# iND83216 register map
Vendor: Indiemicro; Series: RealplumTiny; File version: 1.00
High performance IC
CPU: CM0 r0p1, selectable endian, no MPU, no FPU, 4 interrupt priority bits
Registers are 32-bit, read-write, no defined reset value unless marked. A register's access mark holds for its fields unless they carry their own. Offsets are from the block's base; lines under a group give offsets from that group; [hi:lo] are bit positions; {n}, {i} and the like mark numbered series; 'fields as' and 'values as' point back to an identical list; <NAME> marks a mode.

## Memory map
0x50000000 CRGA size 0x400 — Clock & Reset Generator
0x50000400 PMUA size 0x400 — Power Management Unit
0x50000800 SYSCTRLA size 0x100 — System configuration and retention memory
0x50000900 TRIMHV size 0x100 — Trim bits & Control bits in 5V power domain
0x50000C00 IOCTRLA size 0x400 — I/O configuration and DFT pin control
0x50001000 WICA size 0x400 — WakeUp Interrupt Controller in CPU Deepsleep Mode
0x50001400 WDTA size 0x400 — Watchdog Timer Registers
0x50004400 GPIO size 0x400 — GPIO bit control and configuration
0x50010000 PWM size 0x800 — Control (and status) registers for the pulse width modulation waveform generator.
0x50010800 PWM_AUX size 0x400 — Control (and status) registers for the pulse width modulation waveform generator.
0x50010C00 LINM size 0x400 — LIN master interface registers
0x50011C00 LINS size 0x400 — LIN slave interface registers
0x50013000 EVTHOLD size 0x400 — Event Hold Control
0x50013400 SAR_CTRL size 0x400 — SAR ADC Interface registers
0x50015400 UART0 size 0x400 — UART Interface registers
0x50020000 SYSCFG size 0x1000 — System Configuration Located in Power Down Domain.
0x50021000 FLASH size 0x1000 — Control (and status) registers for FMC
0x50022000 TIMER0 size 0x8 — General purpose timer 0 registers
0x50022008 TIMER1 size 0x8 — General purpose timer 1 registers
0x50022010 TIMER2 size 0x8 — General purpose timer 2 registers
0x50022018 WDT1 size 0x8 — The watchdog timer that is local to VERNE MCU
0x50022100 CRC size 0x10 — CRC32 Registers.

## WICA — WakeUp Interrupt Controller in CPU Deepsleep Mode
Base 0x50001000; register names take the prefix WICA_
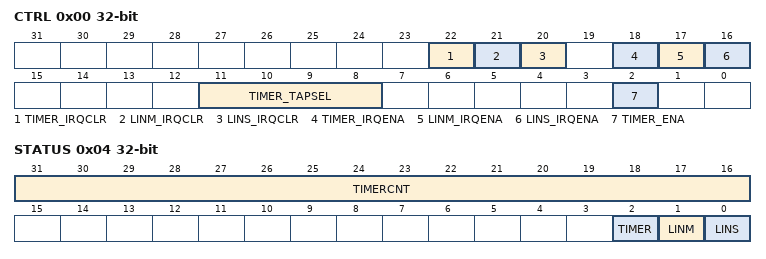
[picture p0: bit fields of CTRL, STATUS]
0x00 CTRL — Wakeup Control Register
  [22] TIMER_IRQCLR wo — clear the wutimer_irq. writting a '1 to this register will clear the wutimer_irq
  [21] LINM_IRQCLR wo — clear the wulinm_irq. writting a '1 to this register will clear the wulinm_irq
  [20] LINS_IRQCLR wo — clear the wulins_irq. writting a '1 to this register will clear the wulins_irq
  [18] TIMER_IRQENA — Timer Wakeup Interrupt Enable. if set, wutimer_irq is asserted if wakeup timer matches the tapsel
  [17] LINM_IRQENA — LIN Master Wakeup Interrupt Enable. if set, wulin_irq is asserted if a wakeup signal is detected on the LIN_OUT bus
  [16] LINS_IRQENA — LIN Slave Wakeup Interrupt Enable. if set, wulin_irq is asserted if a wakeup signal is detected on the LIN_IN bus
  [11:8] TIMER_TAPSEL — WakeUp Timer Tap Select. Wakeup Time = 2^(WUT_TAPSEL) x Tlfclk(62.5us)
  [2] TIMER_ENA — Wakeup Timer Enable. it enables the wakeup timer
0x04 STATUS — Wakeup Status Register
  [31:16] TIMERCNT ro — Wakeup Timer Counter Value. Counter Value of the Wakeup Timer
  [2] TIMER ro — Wakeup Timer Status. This gets set if a wakeup timer is enabled and the count matches the tapsel setting during hibernate, CLRIRQ clears this Register
  [1] LINM ro — LIN Master Wakeup Status. This gets set if a wakeup signal is detected on the LIN_OUT bus when LINM SLEEP bit is set. CLRIRQ clears this Register
  [0] LINS ro — LIN Slave Wakeup Status. This gets set if a wakeup signal is detected on the LIN_IN bus when LINS SLEEP bit is set. CLRIRQ clears this Register

## WDTA — Watchdog Timer Registers
Base 0x50001400; register names take the prefix WDTA_
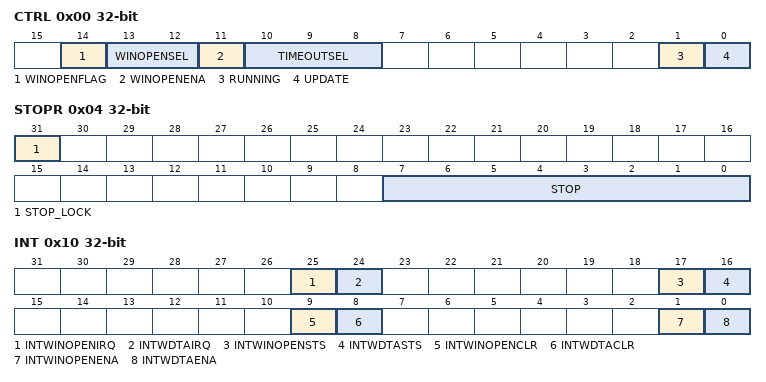
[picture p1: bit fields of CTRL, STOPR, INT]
0x00 CTRL — Control
  [14] WINOPENFLAG ro — Window open flag. A flag that indicates when the watchdog window is open. It only can be cleared by Reg CLEAR!0x0: Window is Closed0x1: Window is Open
  [13:12] WINOPENSEL — Window Mode open select. Defines the time of beginning of watchdog window open (the time between the watchdog start and the window open).0x0: 1/2 * WDT timeout0x1: 1/4 * WDT timeout0x2: 1/8 * WDT timeout0x3: 1/16* WDT timeout
  [11] WINOPENENA — Window Mode Enable. Enables Window Mode. 1'b1: Enable the Window mode of Watchdog, if the WDT is cleared before the time window opens, the WDT will issue a system reset. 1'b0: Disable the Window mode of Watchdog.
  [10:8] TIMEOUTSEL — Timeout select. Defines the watchdog timeout period (the time between a clear operation and the next timeout).0x0: 2^11 * 64us ~= 131 ms0x1: 2^12 * 64us ~= 262 ms0x2: 2^13 * 64us ~= 524 ms0x3: 2^14 * 64us ~= 1.05 s 0x4: 2^15 * 64us ~= 2.10 s 0x5: 2^16 * 64us ~= 4.19 s 0x6: 2^17 * 64us ~= 8.38 s 0x7: 2^18 * 64us ~= 16.77 s
  [1] RUNNING ro — Running status. A flag that indicates when the watchdog timer is enabled.0x0: Watchdog timer is stopped and cleared0x1: Watchdog timer is running
  [0] UPDATE — Window Mode Enable. Set to update Analog-Watchdog Configurations. NOTE: DO NOT change the CTRL register when it is high, which indicates there is an update in progress, It gets cleared by the core when the current update is done
0x04 STOPR — Stop
  [31] STOP_LOCK — Set Only bit. Set this bit to lock STOP bits.
  [7:0] STOP — Stop. Write the *stop* code (0xc3) to this register to reset the timer and disable the watchdog (e.g. during debug). If any other value is written to this register the watchdog will be enabled.
0x08 CLEAR
  [31:0] CLEAR wo — Clear. Write the value 0x3c574ad6 (as a single word access) to reset the watchdog timer. Periodically performing this action is the expected method of preventing the watchdog from timing out (and resetting the MCU).
0x0C CNTVAL — Counter value
  [31:0] CNTVAL ro — Counter value. The instantaneous value of watchdog timeout counter NOTE:This register should read three times and discard the one that is neither not the same with nor adjacent to the other two.
0x10 INT — WDTA Interrupts
  [25] INTWINOPENIRQ ro — Window Open Interrupt.
  [24] INTWDTAIRQ ro — WDTA timeout Interrupt.
  [17] INTWINOPENSTS ro — Window Open Status. Set by WDTA window open
  [16] INTWDTASTS ro — WDTA timeout Status. Set by WDTA timeout
  [9] INTWINOPENCLR wo — Window Open Interrupt Clear. Autoclear: includes a synchronous reset signal which clears the register on the cycle following write.
  [8] INTWDTACLR wo — WDTA timeout Interrupt Clear. Autoclear: includes a synchronous reset signal which clears the register on the cycle following write.
  [1] INTWINOPENENA — Window Open Interrupt Enable.
  [0] INTWDTAENA — WDTA timeout Interrupt Enable.
